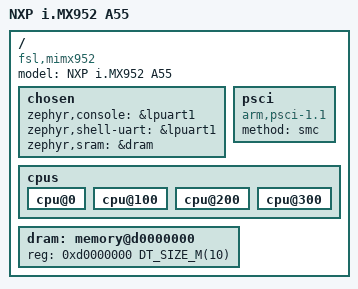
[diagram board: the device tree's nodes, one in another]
/*
 * SPDX-FileCopyrightText: Copyright 2026 NXP
 *
 * SPDX-License-Identifier: Apache-2.0
 */

/dts-v1/;

#include "imx952_evk_mimx9529_a55.dts"

/ {
	model = "NXP i.MX952 A55";
	compatible = "fsl,mimx952";

	chosen {
		zephyr,console = &lpuart1;
		zephyr,shell-uart = &lpuart1;
		/* sram node actually locates at DDR DRAM */
		zephyr,sram = &dram;
	};

	psci {
		compatible = "arm,psci-1.1";
		method = "smc";
	};

	cpus {
		cpu@0 {
			status = "okay";
		};

		cpu@100 {
			status = "okay";
		};

		cpu@200 {
			status = "okay";
		};

		cpu@300 {
			status = "okay";
		};
	};

	dram: memory@d0000000 {
		reg = <0xd0000000 DT_SIZE_M(10)>;
	};
};
